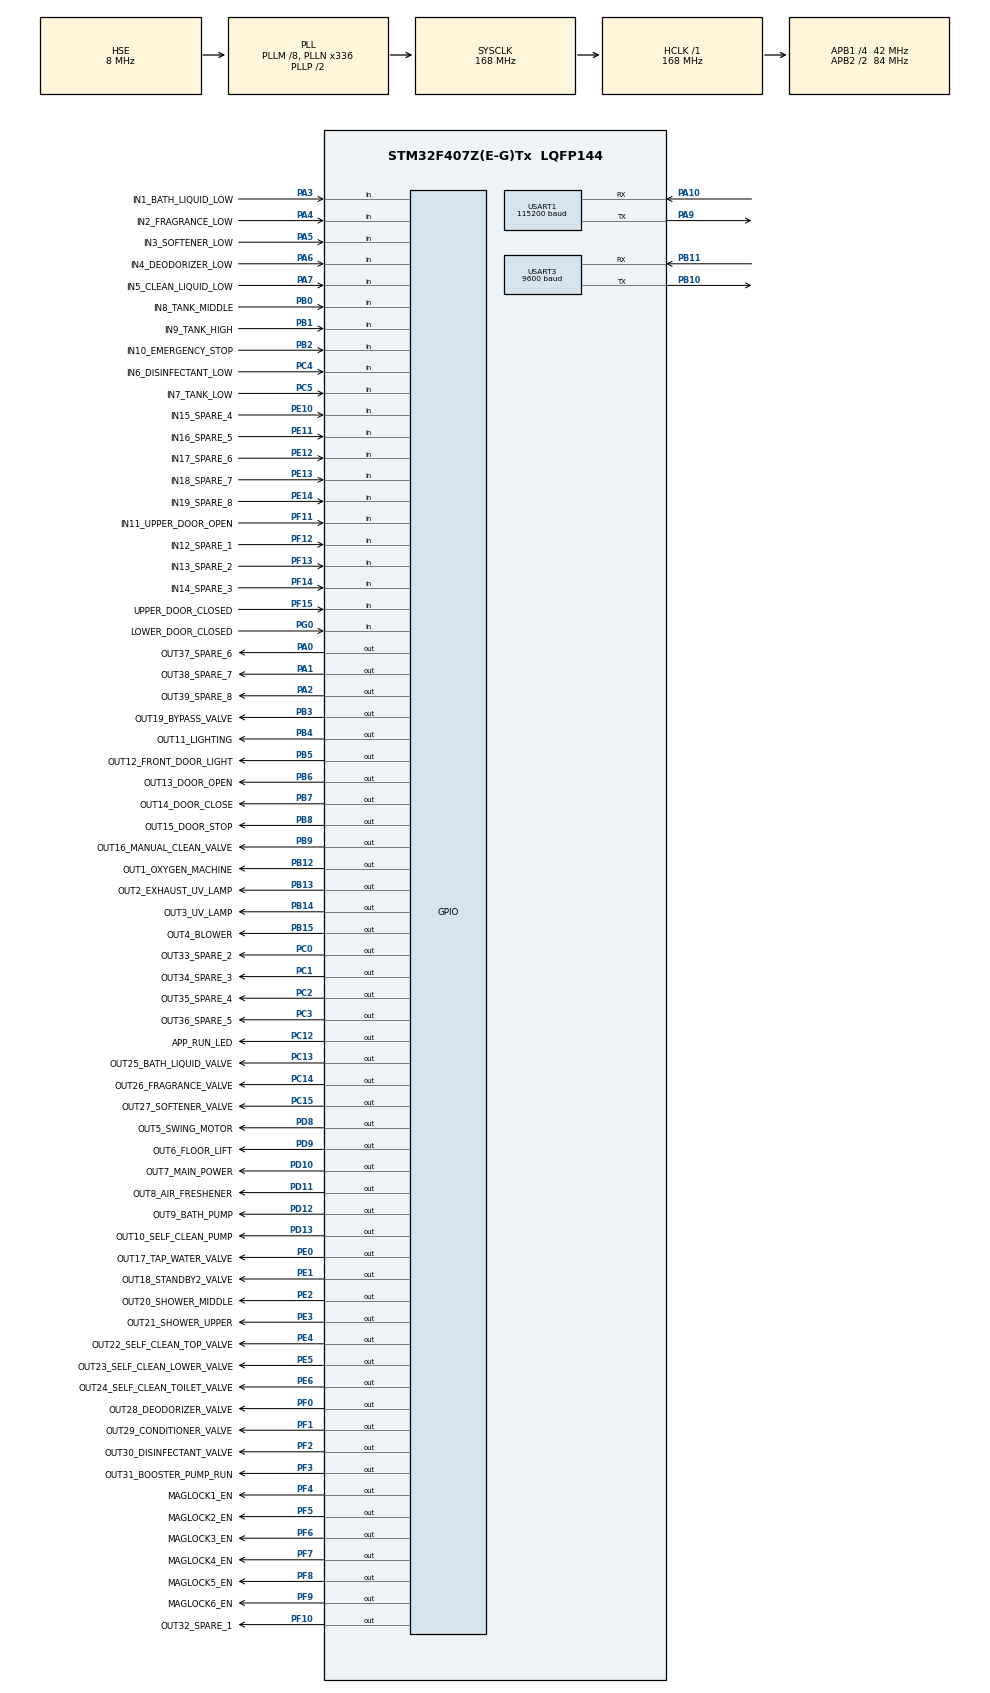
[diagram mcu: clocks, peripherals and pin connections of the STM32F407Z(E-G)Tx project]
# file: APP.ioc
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FREERTOS.Tasks01=defaultTask,24,128,StartDefaultTask,Default,NULL,Dynamic,NULL,NULL
Mcu.Family=STM32F4
Mcu.Name=STM32F407Z(E-G)Tx
Mcu.Package=LQFP144
NVIC.PriorityGroup=NVIC_PRIORITYGROUP_4
NVIC.TIM7_IRQn=true\:15\:0\:false\:false\:true\:false\:false\:true\:true
NVIC.TimeBase=TIM7_IRQn
NVIC.TimeBaseIP=TIM7
NVIC.USART1_IRQn=true\:5\:0\:false\:false\:true\:true\:true\:true\:true
PA10.Mode=Asynchronous
PA10.Signal=USART1_RX
PA13.Mode=Serial_Wire
PA13.Signal=SYS_JTMS-SWDIO
PA14.Mode=Serial_Wire
PA14.Signal=SYS_JTCK-SWCLK
PA9.Mode=Asynchronous
PA9.Signal=USART1_TX
PB10.Mode=Asynchronous
PB10.Signal=USART3_TX
PB11.Mode=Asynchronous
PB11.Signal=USART3_RX
PC12.GPIO_Label=APP_RUN_LED
PC12.PinState=GPIO_PIN_RESET
PC12.Signal=GPIO_Output
PB12.GPIO_Label=OUT1_OXYGEN_MACHINE
PB12.PinState=GPIO_PIN_SET
PB12.Signal=GPIO_Output
PB13.GPIO_Label=OUT2_EXHAUST_UV_LAMP
PB13.PinState=GPIO_PIN_SET
PB13.Signal=GPIO_Output
PB14.GPIO_Label=OUT3_UV_LAMP
PB14.PinState=GPIO_PIN_SET
PB14.Signal=GPIO_Output
PB15.GPIO_Label=OUT4_BLOWER
PB15.PinState=GPIO_PIN_SET
PB15.Signal=GPIO_Output
PD8.GPIO_Label=OUT5_SWING_MOTOR
PD8.PinState=GPIO_PIN_SET
PD8.Signal=GPIO_Output
PD9.GPIO_Label=OUT6_FLOOR_LIFT
PD9.PinState=GPIO_PIN_SET
PD9.Signal=GPIO_Output
PD10.GPIO_Label=OUT7_MAIN_POWER
PD10.PinState=GPIO_PIN_SET
PD10.Signal=GPIO_Output
PD11.GPIO_Label=OUT8_AIR_FRESHENER
PD11.PinState=GPIO_PIN_SET
PD11.Signal=GPIO_Output
PD12.GPIO_Label=OUT9_BATH_PUMP
PD12.PinState=GPIO_PIN_SET
PD12.Signal=GPIO_Output
PD13.GPIO_Label=OUT10_SELF_CLEAN_PUMP
PD13.PinState=GPIO_PIN_SET
PD13.Signal=GPIO_Output
PB4.GPIO_Label=OUT11_LIGHTING
PB4.PinState=GPIO_PIN_SET
PB4.Signal=GPIO_Output
PB5.GPIO_Label=OUT12_FRONT_DOOR_LIGHT
PB5.PinState=GPIO_PIN_SET
PB5.Signal=GPIO_Output
PB6.GPIO_Label=OUT13_DOOR_OPEN
PB6.PinState=GPIO_PIN_SET
PB6.Signal=GPIO_Output
PB7.GPIO_Label=OUT14_DOOR_CLOSE
PB7.PinState=GPIO_PIN_SET
PB7.Signal=GPIO_Output
PB8.GPIO_Label=OUT15_DOOR_STOP
PB8.PinState=GPIO_PIN_SET
PB8.Signal=GPIO_Output
PB9.GPIO_Label=OUT16_MANUAL_CLEAN_VALVE
PB9.PinState=GPIO_PIN_SET
PB9.Signal=GPIO_Output
PE0.GPIO_Label=OUT17_TAP_WATER_VALVE
PE0.PinState=GPIO_PIN_SET
PE0.Signal=GPIO_Output
PE1.GPIO_Label=OUT18_STANDBY2_VALVE
PE1.PinState=GPIO_PIN_SET
PE1.Signal=GPIO_Output
PB3.GPIO_Label=OUT19_BYPASS_VALVE
PB3.PinState=GPIO_PIN_SET
PB3.Signal=GPIO_Output
PE2.GPIO_Label=OUT20_SHOWER_MIDDLE
PE2.PinState=GPIO_PIN_SET
PE2.Signal=GPIO_Output
PE3.GPIO_Label=OUT21_SHOWER_UPPER
PE3.PinState=GPIO_PIN_SET
PE3.Signal=GPIO_Output
PE4.GPIO_Label=OUT22_SELF_CLEAN_TOP_VALVE
PE4.PinState=GPIO_PIN_SET
PE4.Signal=GPIO_Output
PE5.GPIO_Label=OUT23_SELF_CLEAN_LOWER_VALVE
PE5.PinState=GPIO_PIN_SET
PE5.Signal=GPIO_Output
PE6.GPIO_Label=OUT24_SELF_CLEAN_TOILET_VALVE
PE6.PinState=GPIO_PIN_SET
PE6.Signal=GPIO_Output
PC13-ANTI_TAMP.GPIO_Label=OUT25_BATH_LIQUID_VALVE
PC13-ANTI_TAMP.PinState=GPIO_PIN_SET
PC13-ANTI_TAMP.Signal=GPIO_Output
PC14-OSC32_IN.GPIO_Label=OUT26_FRAGRANCE_VALVE
PC14-OSC32_IN.PinState=GPIO_PIN_SET
PC14-OSC32_IN.Signal=GPIO_Output
PC15-OSC32_OUT.GPIO_Label=OUT27_SOFTENER_VALVE
PC15-OSC32_OUT.PinState=GPIO_PIN_SET
PC15-OSC32_OUT.Signal=GPIO_Output
PF0.GPIO_Label=OUT28_DEODORIZER_VALVE
PF0.PinState=GPIO_PIN_SET
PF0.Signal=GPIO_Output
PF1.GPIO_Label=OUT29_CONDITIONER_VALVE
PF1.PinState=GPIO_PIN_SET
PF1.Signal=GPIO_Output
PF2.GPIO_Label=OUT30_DISINFECTANT_VALVE
PF2.PinState=GPIO_PIN_SET
PF2.Signal=GPIO_Output
PF3.GPIO_Label=OUT31_BOOSTER_PUMP_RUN
PF3.PinState=GPIO_PIN_SET
PF3.Signal=GPIO_Output
PF10.GPIO_Label=OUT32_SPARE_1
PF10.PinState=GPIO_PIN_SET
PF10.Signal=GPIO_Output
PC0.GPIO_Label=OUT33_SPARE_2
PC0.PinState=GPIO_PIN_SET
PC0.Signal=GPIO_Output
PC1.GPIO_Label=OUT34_SPARE_3
PC1.PinState=GPIO_PIN_SET
PC1.Signal=GPIO_Output
PC2.GPIO_Label=OUT35_SPARE_4
PC2.PinState=GPIO_PIN_SET
PC2.Signal=GPIO_Output
PC3.GPIO_Label=OUT36_SPARE_5
PC3.PinState=GPIO_PIN_SET
PC3.Signal=GPIO_Output
PA0-WKUP.GPIO_Label=OUT37_SPARE_6
PA0-WKUP.PinState=GPIO_PIN_SET
PA0-WKUP.Signal=GPIO_Output
PA1.GPIO_Label=OUT38_SPARE_7
PA1.PinState=GPIO_PIN_SET
PA1.Signal=GPIO_Output
PA2.GPIO_Label=OUT39_SPARE_8
PA2.PinState=GPIO_PIN_SET
PA2.Signal=GPIO_Output
PF4.GPIO_Label=MAGLOCK1_EN
PF4.PinState=GPIO_PIN_SET
PF4.Signal=GPIO_Output
PF5.GPIO_Label=MAGLOCK2_EN
PF5.PinState=GPIO_PIN_SET
PF5.Signal=GPIO_Output
PF6.GPIO_Label=MAGLOCK3_EN
PF6.PinState=GPIO_PIN_SET
PF6.Signal=GPIO_Output
PF7.GPIO_Label=MAGLOCK4_EN
PF7.PinState=GPIO_PIN_SET
PF7.Signal=GPIO_Output
PF8.GPIO_Label=MAGLOCK5_EN
PF8.PinState=GPIO_PIN_SET
PF8.Signal=GPIO_Output
PF9.GPIO_Label=MAGLOCK6_EN
PF9.PinState=GPIO_PIN_SET
PF9.Signal=GPIO_Output
PH0-OSC_IN.Mode=HSE-External-Oscillator
PH0-OSC_IN.Signal=RCC_OSC_IN
PH1-OSC_OUT.Mode=HSE-External-Oscillator
PH1-OSC_OUT.Signal=RCC_OSC_OUT
ProjectManager.HeapSize=0x200
ProjectManager.StackSize=0x400
ProjectManager.TargetToolchain=CMake
RCC.48MHZClocksFreq_Value=84000000
RCC.AHBFreq_Value=168000000
RCC.APB1CLKDivider=RCC_HCLK_DIV4
RCC.APB1Freq_Value=42000000
RCC.APB1TimFreq_Value=84000000
RCC.APB2CLKDivider=RCC_HCLK_DIV2
RCC.APB2Freq_Value=84000000
RCC.APB2TimFreq_Value=168000000
RCC.CortexFreq_Value=168000000
RCC.HCLKFreq_Value=168000000
RCC.HSE_VALUE=8000000
RCC.HSI_VALUE=16000000
RCC.LSE_VALUE=32768
RCC.PLLM=8
RCC.PLLN=336
RCC.PLLSourceVirtual=RCC_PLLSOURCE_HSE
RCC.SYSCLKFreq_VALUE=168000000
RCC.SYSCLKSource=RCC_SYSCLKSOURCE_PLLCLK
RCC.VCOOutputFreq_Value=336000000
USART1.BaudRate=115200
USART1.VirtualMode=VM_ASYNC
USART3.BaudRate=9600
USART3.VirtualMode=VM_ASYNC
VP_FREERTOS_VS_CMSIS_V2.Mode=CMSIS_V2
VP_SYS_VS_tim7.Mode=TIM7
board=custom
PA3.GPIO_Label=IN1_BATH_LIQUID_LOW
PA3.GPIO_PuPd=GPIO_PULLUP
PA3.Signal=GPIO_Input
PA4.GPIO_Label=IN2_FRAGRANCE_LOW
PA4.GPIO_PuPd=GPIO_PULLUP
PA4.Signal=GPIO_Input
PA5.GPIO_Label=IN3_SOFTENER_LOW
PA5.GPIO_PuPd=GPIO_PULLUP
PA5.Signal=GPIO_Input
PA6.GPIO_Label=IN4_DEODORIZER_LOW
PA6.GPIO_PuPd=GPIO_PULLUP
PA6.Signal=GPIO_Input
PA7.GPIO_Label=IN5_CLEAN_LIQUID_LOW
PA7.GPIO_PuPd=GPIO_PULLUP
PA7.Signal=GPIO_Input
PC4.GPIO_Label=IN6_DISINFECTANT_LOW
PC4.GPIO_PuPd=GPIO_PULLUP
PC4.Signal=GPIO_Input
PC5.GPIO_Label=IN7_TANK_LOW
PC5.GPIO_PuPd=GPIO_PULLUP
PC5.Signal=GPIO_Input
PB0.GPIO_Label=IN8_TANK_MIDDLE
PB0.GPIO_PuPd=GPIO_PULLUP
PB0.Signal=GPIO_Input
PB1.GPIO_Label=IN9_TANK_HIGH
PB1.GPIO_PuPd=GPIO_PULLUP
PB1.Signal=GPIO_Input
PB2.GPIO_Label=IN10_EMERGENCY_STOP
PB2.GPIO_PuPd=GPIO_PULLUP
PB2.Signal=GPIO_Input
PF11.GPIO_Label=IN11_UPPER_DOOR_OPEN
PF11.GPIO_PuPd=GPIO_PULLUP
PF11.Signal=GPIO_Input
PF12.GPIO_Label=IN12_SPARE_1
PF12.GPIO_PuPd=GPIO_PULLUP
PF12.Signal=GPIO_Input
PF13.GPIO_Label=IN13_SPARE_2
PF13.GPIO_PuPd=GPIO_PULLUP
PF13.Signal=GPIO_Input
PF14.GPIO_Label=IN14_SPARE_3
PF14.GPIO_PuPd=GPIO_PULLUP
PF14.Signal=GPIO_Input
PE10.GPIO_Label=IN15_SPARE_4
PE10.GPIO_PuPd=GPIO_PULLUP
PE10.Signal=GPIO_Input
PE11.GPIO_Label=IN16_SPARE_5
PE11.GPIO_PuPd=GPIO_PULLUP
PE11.Signal=GPIO_Input
PE12.GPIO_Label=IN17_SPARE_6
PE12.GPIO_PuPd=GPIO_PULLUP
PE12.Signal=GPIO_Input
PE13.GPIO_Label=IN18_SPARE_7
PE13.GPIO_PuPd=GPIO_PULLUP
PE13.Signal=GPIO_Input
PE14.GPIO_Label=IN19_SPARE_8
PE14.GPIO_PuPd=GPIO_PULLUP
PE14.Signal=GPIO_Input
PF15.GPIO_Label=UPPER_DOOR_CLOSED
PF15.GPIO_PuPd=GPIO_PULLUP
PF15.Signal=GPIO_Input
PG0.GPIO_Label=LOWER_DOOR_CLOSED
PG0.GPIO_PuPd=GPIO_PULLUP
PG0.Signal=GPIO_Input

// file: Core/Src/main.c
/* USER CODE BEGIN Header */
/**
  ******************************************************************************
  * @file           : main.c
  * @brief          : Main program body
  ******************************************************************************
  * @attention
  *
  * Copyright (c) 2026 STMicroelectronics.
  * All rights reserved.
  *
  * This software is licensed under terms that can be found in the LICENSE file
  * in the root directory of this software component.
  * If no LICENSE file comes with this software, it is provided AS-IS.
  *
  ******************************************************************************
  */
/* USER CODE END Header */
#include "main.h"
#include "cmsis_os.h"

/* USER CODE BEGIN Includes */
#include "app_param.h"
#include "app_iap.h"
#include "auto_device.h"
#include "app_tasks.h"
#include "task_output.h"
#include "task_watchdog.h"

/* USER CODE END Includes */

/* USER CODE BEGIN PD */
#define HOST232_RX_BUFFER_SIZE 128U
#define APP_RUN_LED_AUTO_BLINK_MS 1000U

/* USER CODE END PD */

UART_HandleTypeDef huart1;
UART_HandleTypeDef huart3;

/* Definitions for defaultTask */
osThreadId_t defaultTaskHandle;
const osThreadAttr_t defaultTask_attributes = {
  .name = "defaultTask",
  .stack_size = 128 * 4,
  .priority = (osPriority_t) osPriorityNormal,
};
/* USER CODE BEGIN PV */
static const uint8_t host232_start_message[] = "APP START\r\n";
static uint8_t host232_rx_byte;
static uint8_t host232_rx_buffer[HOST232_RX_BUFFER_SIZE];
static volatile uint16_t host232_rx_head;
static volatile uint16_t host232_rx_tail;

/* USER CODE END PV */

void SystemClock_Config(void);
static void MX_GPIO_Init(void);
static void MX_USART1_UART_Init(void);
static void MX_USART3_UART_Init(void);
void StartDefaultTask(void *argument);

/* USER CODE BEGIN PFP */
static void AppRunLed_Blink(uint8_t count, uint32_t period_ms);

/* USER CODE END PFP */

/* USER CODE BEGIN 0 */
static void AppRunLed_Blink(uint8_t count, uint32_t period_ms)
{
  uint8_t index;

  for (index = 0U; index < count; ++index)
  {
    HAL_GPIO_WritePin(APP_RUN_LED_GPIO_Port, APP_RUN_LED_Pin, GPIO_PIN_SET);
    HAL_Delay(period_ms);
    HAL_GPIO_WritePin(APP_RUN_LED_GPIO_Port, APP_RUN_LED_Pin, GPIO_PIN_RESET);
    HAL_Delay(period_ms);
  }
}

/* USER CODE END 0 */

int main(void)
{

  /* MCU Configuration--------------------------------------------------------*/

  /* Reset of all peripherals, Initializes the Flash interface and the Systick. */
  HAL_Init();

  /* USER CODE BEGIN Init */
  if (HAL_RCC_DeInit() != HAL_OK)
  {
    Error_Handler();
  }

  /* USER CODE END Init */

  /* Configure the system clock */
  SystemClock_Config();

  /* Initialize all configured peripherals */
  MX_GPIO_Init();
  AutoDevice_Init();
  TaskOutput_InitHardware();
  MX_USART1_UART_Init();
  MX_USART3_UART_Init();
  /* USER CODE BEGIN 2 */
  AppRunLed_Blink(1U, 80U);
  HAL_Delay(200U);

  SCB->VTOR = FLASH_BASE + VECT_TAB_OFFSET;
  __DSB();
  __ISB();

  HAL_NVIC_ClearPendingIRQ(USART1_IRQn);
  __enable_irq();

  if (UART2_Send(host232_start_message,
                 (uint16_t)(sizeof(host232_start_message) - 1U)) != HAL_OK)
  {
    Error_Handler();
  }

  AppParam_Init();

  if (HAL_UART_Receive_IT(&huart1, &host232_rx_byte, 1U) != HAL_OK)
  {
    Error_Handler();
  }

  /* USER CODE END 2 */

  /* Init scheduler */
  osKernelInitialize();

  /* Create the thread(s) */
  /* creation of defaultTask */
  defaultTaskHandle = osThreadNew(StartDefaultTask, NULL, &defaultTask_attributes);

  /* USER CODE BEGIN RTOS_THREADS */
  AppTasks_Create();
  /* USER CODE END RTOS_THREADS */

  /* Start scheduler */
  osKernelStart();

  /* We should never get here as control is now taken by the scheduler */

  /* Infinite loop */
  while (1)
  {

  }
}

void SystemClock_Config(void)
{
  RCC_OscInitTypeDef RCC_OscInitStruct = {0};
  RCC_ClkInitTypeDef RCC_ClkInitStruct = {0};

  /** Configure the main internal regulator output voltage
  */
  __HAL_RCC_PWR_CLK_ENABLE();
  __HAL_PWR_VOLTAGESCALING_CONFIG(PWR_REGULATOR_VOLTAGE_SCALE1);

  /** Initializes the RCC Oscillators according to the specified parameters
  * in the RCC_OscInitTypeDef structure.
  */
  RCC_OscInitStruct.OscillatorType = RCC_OSCILLATORTYPE_HSE;
  RCC_OscInitStruct.HSEState = RCC_HSE_ON;
  RCC_OscInitStruct.PLL.PLLState = RCC_PLL_ON;
  RCC_OscInitStruct.PLL.PLLSource = RCC_PLLSOURCE_HSE;
  RCC_OscInitStruct.PLL.PLLM = 8;
  RCC_OscInitStruct.PLL.PLLN = 336;
  RCC_OscInitStruct.PLL.PLLP = RCC_PLLP_DIV2;
  RCC_OscInitStruct.PLL.PLLQ = 4;
  if (HAL_RCC_OscConfig(&RCC_OscInitStruct) != HAL_OK)
  {
    Error_Handler();
  }

  /** Initializes the CPU, AHB and APB buses clocks
  */
  RCC_ClkInitStruct.ClockType = RCC_CLOCKTYPE_HCLK|RCC_CLOCKTYPE_SYSCLK
                              |RCC_CLOCKTYPE_PCLK1|RCC_CLOCKTYPE_PCLK2;
  RCC_ClkInitStruct.SYSCLKSource = RCC_SYSCLKSOURCE_PLLCLK;
  RCC_ClkInitStruct.AHBCLKDivider = RCC_SYSCLK_DIV1;
  RCC_ClkInitStruct.APB1CLKDivider = RCC_HCLK_DIV4;
  RCC_ClkInitStruct.APB2CLKDivider = RCC_HCLK_DIV2;

  if (HAL_RCC_ClockConfig(&RCC_ClkInitStruct, FLASH_LATENCY_5) != HAL_OK)
  {
    Error_Handler();
  }
}

static void MX_USART1_UART_Init(void)
{

  huart1.Instance = USART1;
  huart1.Init.BaudRate = 115200;
  huart1.Init.WordLength = UART_WORDLENGTH_8B;
  huart1.Init.StopBits = UART_STOPBITS_1;
  huart1.Init.Parity = UART_PARITY_NONE;
  huart1.Init.Mode = UART_MODE_TX_RX;
  huart1.Init.HwFlowCtl = UART_HWCONTROL_NONE;
  huart1.Init.OverSampling = UART_OVERSAMPLING_16;
  if (HAL_UART_Init(&huart1) != HAL_OK)
  {
    Error_Handler();
  }

}

static void MX_USART3_UART_Init(void)
{

  huart3.Instance = USART3;
  huart3.Init.BaudRate = 9600;
  huart3.Init.WordLength = UART_WORDLENGTH_8B;
  huart3.Init.StopBits = UART_STOPBITS_1;
  huart3.Init.Parity = UART_PARITY_NONE;
  huart3.Init.Mode = UART_MODE_TX_RX;
  huart3.Init.HwFlowCtl = UART_HWCONTROL_NONE;
  huart3.Init.OverSampling = UART_OVERSAMPLING_16;
  if (HAL_UART_Init(&huart3) != HAL_OK)
  {
    Error_Handler();
  }

}

static void MX_GPIO_Init(void)
{
  GPIO_InitTypeDef GPIO_InitStruct = {0};

  /* GPIO Ports Clock Enable */
  __HAL_RCC_GPIOC_CLK_ENABLE();
  __HAL_RCC_GPIOH_CLK_ENABLE();
  __HAL_RCC_GPIOA_CLK_ENABLE();
  __HAL_RCC_GPIOB_CLK_ENABLE();

  /* APP run and error LEDs are active low. */
  HAL_GPIO_WritePin(APP_ERROR_LED_GPIO_Port, APP_ERROR_LED_Pin, GPIO_PIN_SET);
  HAL_GPIO_WritePin(APP_RUN_LED_GPIO_Port, APP_RUN_LED_Pin, GPIO_PIN_RESET);
  GPIO_InitStruct.Pin = APP_ERROR_LED_Pin|APP_RUN_LED_Pin;
  GPIO_InitStruct.Mode = GPIO_MODE_OUTPUT_PP;
  GPIO_InitStruct.Pull = GPIO_NOPULL;
  GPIO_InitStruct.Speed = GPIO_SPEED_FREQ_LOW;
  HAL_GPIO_Init(APP_RUN_LED_GPIO_Port, &GPIO_InitStruct);

}

/* USER CODE BEGIN 4 */
HAL_StatusTypeDef UART2_Send(const uint8_t *data, uint16_t length)
{
  HAL_StatusTypeDef status;

  if ((data == NULL) || (length == 0U))
  {
    return HAL_ERROR;
  }

  AppIap_TxLock();
  status = HAL_UART_Transmit(&huart1, data, length, HAL_MAX_DELAY);
  AppIap_TxUnlock();
  return status;
}

uint16_t UART2_Read(uint8_t *data, uint16_t max_length)
{
  uint16_t count = 0U;

  if (data == NULL)
  {
    return 0U;
  }

  while ((count < max_length) && (host232_rx_tail != host232_rx_head))
  {
    data[count++] = host232_rx_buffer[host232_rx_tail];
    host232_rx_tail = (uint16_t)((host232_rx_tail + 1U) % HOST232_RX_BUFFER_SIZE);
  }

  return count;
}

void HAL_UART_RxCpltCallback(UART_HandleTypeDef *huart)
{
  if (huart->Instance == USART1)
  {
    uint16_t next_head = (uint16_t)((host232_rx_head + 1U) % HOST232_RX_BUFFER_SIZE);

    if (next_head != host232_rx_tail)
    {
      host232_rx_buffer[host232_rx_head] = host232_rx_byte;
      host232_rx_head = next_head;
    }

    (void)HAL_UART_Receive_IT(&huart1, &host232_rx_byte, 1U);
  }
}

void HAL_UART_ErrorCallback(UART_HandleTypeDef *huart)
{
  if (huart->Instance == USART1)
  {
    (void)HAL_UART_Receive_IT(&huart1, &host232_rx_byte, 1U);
  }
}

/* USER CODE END 4 */

void StartDefaultTask(void *argument)
{
  /* USER CODE BEGIN 5 */
  uint8_t last_auto_mode = 0xFFU;
  uint32_t led_tick = HAL_GetTick();

  (void)argument;
  /* Infinite loop */
  for(;;)
  {
    uint8_t auto_mode = TaskOutput_IsAutoMode();
    uint32_t now = HAL_GetTick();

    if (auto_mode == 0U)
    {
      HAL_GPIO_WritePin(APP_RUN_LED_GPIO_Port, APP_RUN_LED_Pin, GPIO_PIN_RESET);
      last_auto_mode = auto_mode;
      led_tick = now;
    }
    else
    {
      if (last_auto_mode != auto_mode)
      {
        HAL_GPIO_WritePin(APP_RUN_LED_GPIO_Port, APP_RUN_LED_Pin, GPIO_PIN_RESET);
        led_tick = now;
        last_auto_mode = auto_mode;
      }
      else if ((now - led_tick) >= APP_RUN_LED_AUTO_BLINK_MS)
      {
        HAL_GPIO_TogglePin(APP_RUN_LED_GPIO_Port, APP_RUN_LED_Pin);
        led_tick = now;
      }
    }
    osDelay(20);
  }
  /* USER CODE END 5 */
}

void HAL_TIM_PeriodElapsedCallback(TIM_HandleTypeDef *htim)
{
  if (htim->Instance == TIM7)
  {
    HAL_IncTick();
  }
}

void Error_Handler(void)
{
  /* USER CODE BEGIN Error_Handler_Debug */
  GPIO_InitTypeDef GPIO_InitStruct = {0};

  TaskWatchdog_EmergencyOutputsOff();

  __HAL_RCC_GPIOC_CLK_ENABLE();
  HAL_GPIO_WritePin(APP_RUN_LED_GPIO_Port, APP_RUN_LED_Pin, GPIO_PIN_SET);
  HAL_GPIO_WritePin(APP_ERROR_LED_GPIO_Port, APP_ERROR_LED_Pin, GPIO_PIN_SET);

  GPIO_InitStruct.Pin = APP_RUN_LED_Pin|APP_ERROR_LED_Pin;
  GPIO_InitStruct.Mode = GPIO_MODE_OUTPUT_PP;
  GPIO_InitStruct.Pull = GPIO_NOPULL;
  GPIO_InitStruct.Speed = GPIO_SPEED_FREQ_LOW;
  HAL_GPIO_Init(APP_RUN_LED_GPIO_Port, &GPIO_InitStruct);

  while (1)
  {
    HAL_GPIO_TogglePin(APP_ERROR_LED_GPIO_Port, APP_ERROR_LED_Pin);
    HAL_Delay(1000U);
  }
  /* USER CODE END Error_Handler_Debug */
}
